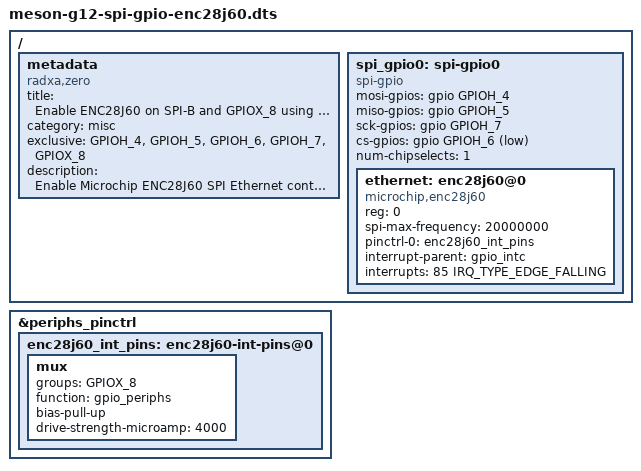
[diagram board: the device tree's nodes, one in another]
/dts-v1/;
/plugin/;

#include <dt-bindings/gpio/gpio.h>
#include <dt-bindings/gpio/meson-g12a-gpio.h>
#include <dt-bindings/interrupt-controller/irq.h>

/ {
	metadata {
		title = "Enable ENC28J60 on SPI-B and GPIOX_8 using software emulation";
		compatible = "radxa,zero";
		category = "misc";
		exclusive = "GPIOH_4", "GPIOH_5", "GPIOH_6", "GPIOH_7", "GPIOX_8";
		description = "Enable Microchip ENC28J60 SPI Ethernet controller on SPI-B.\nThis overlay uses spi-gpio driver, which is slower than hardware SPI.\nINT=GPIOX_8";
	};

	fragment@0 {
		target-path = "/";
		__overlay__ {
			spi_gpio0: spi-gpio0 {
				compatible = "spi-gpio";
				#address-cells = <1>;
				#size-cells = <0>;
				ranges;
				mosi-gpios = <&gpio GPIOH_4 GPIO_ACTIVE_HIGH>;
				miso-gpios = <&gpio GPIOH_5 GPIO_ACTIVE_HIGH>;
				sck-gpios = <&gpio GPIOH_7 GPIO_ACTIVE_HIGH>;
				cs-gpios = <&gpio GPIOH_6 GPIO_ACTIVE_LOW>;
				num-chipselects = <1>;
				status = "okay";

				ethernet: enc28j60@0 {
					compatible = "microchip,enc28j60";
					reg = <0>;
					spi-max-frequency = <20000000>;

					pinctrl-names = "default";
					pinctrl-0 = <&enc28j60_int_pins>;

					interrupt-parent = <&gpio_intc>;
					interrupts = <85 IRQ_TYPE_EDGE_FALLING>;
				};
			};
		};
	};

	fragment@1 {
		target = <&periphs_pinctrl>;
		__overlay__ {
			enc28j60_int_pins: enc28j60-int-pins@0 {
				mux {
					groups = "GPIOX_8";
					function = "gpio_periphs";
					bias-pull-up;
					drive-strength-microamp = <4000>;
				};
			};
		};
	};
};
